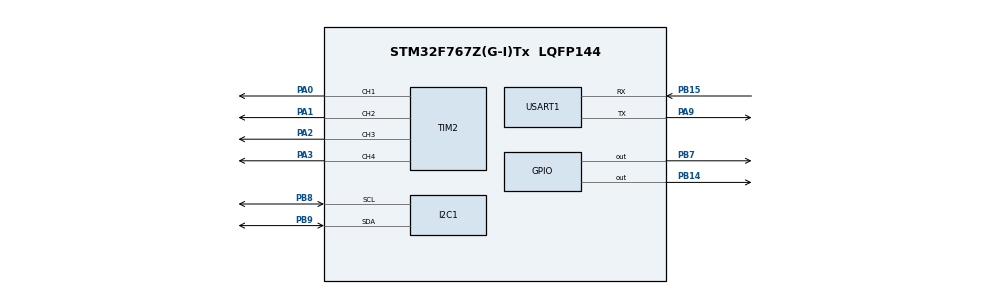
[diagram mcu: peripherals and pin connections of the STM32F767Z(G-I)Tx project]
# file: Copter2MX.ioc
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FATFS._USE_BUFF_WO_ALIGNMENT=2
FATFS._USE_ERASE=0
FREERTOS.INCLUDE_vTaskDelayUntil=1
FREERTOS.Tasks01=defaultTask,0,128,StartDefaultTask,Default,NULL,Dynamic,NULL,NULL;IMUTask,0,1024,ReadIMU,As external,NULL,Dynamic,NULL,NULL;DebugTask,-3,1024,WriteDebug,As external,NULL,Dynamic,NULL,NULL;PWMTask,0,1024,SetPWMOutput,As external,NULL,Dynamic,NULL,NULL;controllerTask,3,1024,StartController,As external,NULL,Dynamic,NULL,NULL
FREERTOS.configTOTAL_HEAP_SIZE=131072
FREERTOS.configUSE_ALTERNATIVE_API=0
I2C1.OwnAddress2Masks=I2C_OA2_NOMASK
Mcu.Family=STM32F7
Mcu.Name=STM32F767Z(G-I)Tx
Mcu.Package=LQFP144
NVIC.PriorityGroup=NVIC_PRIORITYGROUP_4
NVIC.USART1_IRQn=true\:5\:0\:false\:false\:true\:true
PA0/WKUP.Signal=S_TIM2_CH1_ETR
PA1.Signal=S_TIM2_CH2
PA2.Signal=S_TIM2_CH3
PA3.Signal=S_TIM2_CH4
PA9.Mode=Asynchronous
PA9.Signal=USART1_TX
PB14.Signal=GPIO_Output
PB15.Mode=Asynchronous
PB15.Signal=USART1_RX
PB7.Signal=GPIO_Output
PB8.Mode=I2C
PB8.Signal=I2C1_SCL
PB9.Mode=I2C
PB9.Signal=I2C1_SDA
ProjectManager.HeapSize=0x200
ProjectManager.StackSize=0x400
ProjectManager.TargetToolchain=SW4STM32
RCC.CECEnable=false
RCC.ClockTypeHCLK=RCC_CLOCKTYPE_HCLK
RCC.ClockTypePCLK1=RCC_CLOCKTYPE_PCLK1
RCC.ClockTypePCLK2=RCC_CLOCKTYPE_PCLK2
RCC.ClockTypeSysClk=RCC_CLOCKTYPE_SYSCLK
RCC.EnableHSE=false
RCC.EnableHSERTCDevisor=false
RCC.EnableLSE=false
RCC.EnableLSERTC=false
RCC.EnbaleCSS=false
RCC.ExtClockEnable=false
RCC.HSEState=RCC_HSE_OFF
RCC.HSE_VALUE=25000000
RCC.HSIState=RCC_HSI_ON
RCC.HSI_VALUE=16000000
RCC.I2C1Enable=true
RCC.I2C2Enable=false
RCC.I2C3Enable=false
RCC.I2C4Enable=false
RCC.I2SEnable=false
RCC.LCDEnable=false
RCC.LPTIM1Enable=false
RCC.LSE_VALUE=32768
RCC.LSIState=RCC_LSI_OFF
RCC.MCO1OutPutEnable=false
RCC.MCO2I2SEnable=false
RCC.MCO2OutPutEnable=false
RCC.OscillatorTypeHSI=RCC_OSCILLATORTYPE_HSI
RCC.PLLState=RCC_PLL_OFF
RCC.RCC_PERIPHCLK_I2C1Var=RCC_PERIPHCLK_I2C1
RCC.RCC_PERIPHCLK_USART1Var=RCC_PERIPHCLK_USART1
RCC.RTCEnable=false
RCC.SAI1Enable=false
RCC.SAI2Enable=false
RCC.SDMMC1Enable=false
RCC.SPDIFEnable=false
RCC.UART4Enable=false
RCC.UART5Enable=false
RCC.UART7Enable=false
RCC.UART8Enable=false
RCC.USART1Enable=true
RCC.USART2Enable=false
RCC.USART3Enable=false
RCC.USART6Enable=false
RCC.USBEnable=false
RCC.USBFreq_Value=96000000
RCC.VCOOutputFreq_Value=192000000
SH.S_TIM2_CH1_ETR.0=TIM2_CH1,PWM Generation1 CH1
SH.S_TIM2_CH2.0=TIM2_CH2,PWM Generation2 CH2
SH.S_TIM2_CH3.0=TIM2_CH3,PWM Generation3 CH3
SH.S_TIM2_CH4.0=TIM2_CH4,PWM Generation4 CH4
TIM2.Channel-PWM\ Generation1\ CH1=TIM_CHANNEL_1
TIM2.Channel-PWM\ Generation2\ CH2=TIM_CHANNEL_2
TIM2.Channel-PWM\ Generation3\ CH3=TIM_CHANNEL_3
TIM2.Channel-PWM\ Generation4\ CH4=TIM_CHANNEL_4
TIM2.ClearInputState=ENABLE
USART1.HwFlowCtl-Asynchronous=UART_HWCONTROL_NONE
USART1.VirtualMode-Asynchronous=VM_ASYNC
USART1.WordLength=WORDLENGTH_8B
VP_FATFS_VS_Generic.Mode=User_defined
VP_FREERTOS_VS_ENABLE.Mode=Enabled
board=Copter2MX

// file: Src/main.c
/**
  ******************************************************************************
  * File Name          : main.c
  * Description        : Main program body
  ******************************************************************************
  *
  * Copyright (c) 2017 STMicroelectronics International N.V.
  * All rights reserved.
  *
  * Redistribution and use in source and binary forms, with or without
  * modification, are permitted, provided that the following conditions are met:
  *
  * 1. Redistribution of source code must retain the above copyright notice,
  *    this list of conditions and the following disclaimer.
  * 2. Redistributions in binary form must reproduce the above copyright notice,
  *    this list of conditions and the following disclaimer in the documentation
  *    and/or other materials provided with the distribution.
  * 3. Neither the name of STMicroelectronics nor the names of other
  *    contributors to this software may be used to endorse or promote products
  *    derived from this software without specific written permission.
  * 4. This software, including modifications and/or derivative works of this
  *    software, must execute solely and exclusively on microcontroller or
  *    microprocessor devices manufactured by or for STMicroelectronics.
  * 5. Redistribution and use of this software other than as permitted under
  *    this license is void and will automatically terminate your rights under
  *    this license.
  *
  * THIS SOFTWARE IS PROVIDED BY STMICROELECTRONICS AND CONTRIBUTORS "AS IS"
  * AND ANY EXPRESS, IMPLIED OR STATUTORY WARRANTIES, INCLUDING, BUT NOT
  * LIMITED TO, THE IMPLIED WARRANTIES OF MERCHANTABILITY, FITNESS FOR A
  * PARTICULAR PURPOSE AND NON-INFRINGEMENT OF THIRD PARTY INTELLECTUAL PROPERTY
  * RIGHTS ARE DISCLAIMED TO THE FULLEST EXTENT PERMITTED BY LAW. IN NO EVENT
  * SHALL STMICROELECTRONICS OR CONTRIBUTORS BE LIABLE FOR ANY DIRECT, INDIRECT,
  * INCIDENTAL, SPECIAL, EXEMPLARY, OR CONSEQUENTIAL DAMAGES (INCLUDING, BUT NOT
  * LIMITED TO, PROCUREMENT OF SUBSTITUTE GOODS OR SERVICES; LOSS OF USE, DATA,
  * OR PROFITS; OR BUSINESS INTERRUPTION) HOWEVER CAUSED AND ON ANY THEORY OF
  * LIABILITY, WHETHER IN CONTRACT, STRICT LIABILITY, OR TORT (INCLUDING
  * NEGLIGENCE OR OTHERWISE) ARISING IN ANY WAY OUT OF THE USE OF THIS SOFTWARE,
  * EVEN IF ADVISED OF THE POSSIBILITY OF SUCH DAMAGE.
  *
  ******************************************************************************
  */
#include "main.h"
#include "stm32f7xx_hal.h"
#include "cmsis_os.h"
#include "fatfs.h"

/* USER CODE BEGIN Includes */
#include "DebugTask.h"
#include "sharedResources.h"

/* USER CODE END Includes */

I2C_HandleTypeDef hi2c1;

TIM_HandleTypeDef htim2;

UART_HandleTypeDef huart1;

osThreadId defaultTaskHandle;
osThreadId IMUTaskHandle;
osThreadId DebugTaskHandle;
osThreadId PWMTaskHandle;
osThreadId controllerTaskHandle;

/* USER CODE BEGIN PV */
/* Private variables ---------------------------------------------------------*/

/* USER CODE END PV */

void SystemClock_Config(void);
void Error_Handler(void);
static void MX_GPIO_Init(void);
static void MX_I2C1_Init(void);
static void MX_USART1_UART_Init(void);
static void MX_TIM2_Init(void);
void StartDefaultTask(void const * argument);
extern void ReadIMU(void const * argument);
extern void WriteDebug(void const * argument);
extern void SetPWMOutput(void const * argument);
extern void StartController(void const * argument);

void HAL_TIM_MspPostInit(TIM_HandleTypeDef *htim);

/* USER CODE BEGIN PFP */
/* Private function prototypes -----------------------------------------------*/

/* USER CODE END PFP */

int main(void)
{

  /* MCU Configuration----------------------------------------------------------*/

  /* Reset of all peripherals, Initializes the Flash interface and the Systick. */
  HAL_Init();

  /* Configure the system clock */
  SystemClock_Config();

  /* Initialize all configured peripherals */
  MX_GPIO_Init();
  MX_I2C1_Init();
  MX_USART1_UART_Init();
  MX_TIM2_Init();

  /* USER CODE BEGIN 2 */
  setDebugUartHandler(&huart1);
  initializeResources();
  /* USER CODE END 2 */

  /* Create the thread(s) */
  /* definition and creation of defaultTask */
  osThreadDef(defaultTask, StartDefaultTask, osPriorityNormal, 0, 128);
  defaultTaskHandle = osThreadCreate(osThread(defaultTask), NULL);

  /* definition and creation of IMUTask */
  osThreadDef(IMUTask, ReadIMU, osPriorityNormal, 0, 1024);
  IMUTaskHandle = osThreadCreate(osThread(IMUTask), NULL);

  /* definition and creation of DebugTask */
  osThreadDef(DebugTask, WriteDebug, osPriorityIdle, 0, 1024);
  DebugTaskHandle = osThreadCreate(osThread(DebugTask), NULL);

  /* definition and creation of PWMTask */
  osThreadDef(PWMTask, SetPWMOutput, osPriorityNormal, 0, 1024);
  PWMTaskHandle = osThreadCreate(osThread(PWMTask), NULL);

  /* definition and creation of controllerTask */
  osThreadDef(controllerTask, StartController, osPriorityRealtime, 0, 1024);
  controllerTaskHandle = osThreadCreate(osThread(controllerTask), NULL);

  /* Start scheduler */
  osKernelStart();

  /* We should never get here as control is now taken by the scheduler */

  /* Infinite loop */
  while (1)
  {

  }

}

/** System Clock Configuration
*/
void SystemClock_Config(void)
{

  RCC_OscInitTypeDef RCC_OscInitStruct;
  RCC_ClkInitTypeDef RCC_ClkInitStruct;
  RCC_PeriphCLKInitTypeDef PeriphClkInitStruct;

    /**Configure the main internal regulator output voltage
    */
  __HAL_RCC_PWR_CLK_ENABLE();

  __HAL_PWR_VOLTAGESCALING_CONFIG(PWR_REGULATOR_VOLTAGE_SCALE3);

    /**Initializes the CPU, AHB and APB busses clocks
    */
  RCC_OscInitStruct.OscillatorType = RCC_OSCILLATORTYPE_HSI;
  RCC_OscInitStruct.HSIState = RCC_HSI_ON;
  RCC_OscInitStruct.HSICalibrationValue = 16;
  RCC_OscInitStruct.PLL.PLLState = RCC_PLL_NONE;
  if (HAL_RCC_OscConfig(&RCC_OscInitStruct) != HAL_OK)
  {
    Error_Handler();
  }

    /**Initializes the CPU, AHB and APB busses clocks
    */
  RCC_ClkInitStruct.ClockType = RCC_CLOCKTYPE_HCLK|RCC_CLOCKTYPE_SYSCLK
                              |RCC_CLOCKTYPE_PCLK1|RCC_CLOCKTYPE_PCLK2;
  RCC_ClkInitStruct.SYSCLKSource = RCC_SYSCLKSOURCE_HSI;
  RCC_ClkInitStruct.AHBCLKDivider = RCC_SYSCLK_DIV1;
  RCC_ClkInitStruct.APB1CLKDivider = RCC_HCLK_DIV1;
  RCC_ClkInitStruct.APB2CLKDivider = RCC_HCLK_DIV1;

  if (HAL_RCC_ClockConfig(&RCC_ClkInitStruct, FLASH_LATENCY_0) != HAL_OK)
  {
    Error_Handler();
  }

  PeriphClkInitStruct.PeriphClockSelection = RCC_PERIPHCLK_USART1|RCC_PERIPHCLK_I2C1;
  PeriphClkInitStruct.Usart1ClockSelection = RCC_USART1CLKSOURCE_PCLK2;
  PeriphClkInitStruct.I2c1ClockSelection = RCC_I2C1CLKSOURCE_PCLK1;
  if (HAL_RCCEx_PeriphCLKConfig(&PeriphClkInitStruct) != HAL_OK)
  {
    Error_Handler();
  }

    /**Configure the Systick interrupt time
    */
  HAL_SYSTICK_Config(HAL_RCC_GetHCLKFreq()/1000);

    /**Configure the Systick
    */
  HAL_SYSTICK_CLKSourceConfig(SYSTICK_CLKSOURCE_HCLK);

  /* SysTick_IRQn interrupt configuration */
  HAL_NVIC_SetPriority(SysTick_IRQn, 15, 0);
}

/* I2C1 init function */
static void MX_I2C1_Init(void)
{

  hi2c1.Instance = I2C1;
  hi2c1.Init.Timing = 0x00303D5B;
  hi2c1.Init.OwnAddress1 = 0;
  hi2c1.Init.AddressingMode = I2C_ADDRESSINGMODE_7BIT;
  hi2c1.Init.DualAddressMode = I2C_DUALADDRESS_DISABLE;
  hi2c1.Init.OwnAddress2 = 0;
  hi2c1.Init.OwnAddress2Masks = I2C_OA2_NOMASK;
  hi2c1.Init.GeneralCallMode = I2C_GENERALCALL_DISABLE;
  hi2c1.Init.NoStretchMode = I2C_NOSTRETCH_DISABLE;
  if (HAL_I2C_Init(&hi2c1) != HAL_OK)
  {
    Error_Handler();
  }

    /**Configure Analogue filter
    */
  if (HAL_I2CEx_ConfigAnalogFilter(&hi2c1, I2C_ANALOGFILTER_ENABLE) != HAL_OK)
  {
    Error_Handler();
  }

    /**Configure Digital filter
    */
  if (HAL_I2CEx_ConfigDigitalFilter(&hi2c1, 0) != HAL_OK)
  {
    Error_Handler();
  }

}

/* TIM2 init function */
static void MX_TIM2_Init(void)
{

  TIM_MasterConfigTypeDef sMasterConfig;
  TIM_OC_InitTypeDef sConfigOC;

  htim2.Instance = TIM2;
  htim2.Init.Prescaler = 0;
  htim2.Init.CounterMode = TIM_COUNTERMODE_UP;
  htim2.Init.Period = 0;
  htim2.Init.ClockDivision = TIM_CLOCKDIVISION_DIV1;
  htim2.Init.AutoReloadPreload = TIM_AUTORELOAD_PRELOAD_DISABLE;
  if (HAL_TIM_PWM_Init(&htim2) != HAL_OK)
  {
    Error_Handler();
  }

  sMasterConfig.MasterOutputTrigger = TIM_TRGO_RESET;
  sMasterConfig.MasterSlaveMode = TIM_MASTERSLAVEMODE_DISABLE;
  if (HAL_TIMEx_MasterConfigSynchronization(&htim2, &sMasterConfig) != HAL_OK)
  {
    Error_Handler();
  }

  sConfigOC.OCMode = TIM_OCMODE_PWM1;
  sConfigOC.Pulse = 0;
  sConfigOC.OCPolarity = TIM_OCPOLARITY_HIGH;
  sConfigOC.OCFastMode = TIM_OCFAST_DISABLE;
  if (HAL_TIM_PWM_ConfigChannel(&htim2, &sConfigOC, TIM_CHANNEL_1) != HAL_OK)
  {
    Error_Handler();
  }

  if (HAL_TIM_PWM_ConfigChannel(&htim2, &sConfigOC, TIM_CHANNEL_2) != HAL_OK)
  {
    Error_Handler();
  }

  if (HAL_TIM_PWM_ConfigChannel(&htim2, &sConfigOC, TIM_CHANNEL_3) != HAL_OK)
  {
    Error_Handler();
  }

  if (HAL_TIM_PWM_ConfigChannel(&htim2, &sConfigOC, TIM_CHANNEL_4) != HAL_OK)
  {
    Error_Handler();
  }

  HAL_TIM_MspPostInit(&htim2);

}

/* USART1 init function */
static void MX_USART1_UART_Init(void)
{

  huart1.Instance = USART1;
  huart1.Init.BaudRate = 115200;
  huart1.Init.WordLength = UART_WORDLENGTH_8B;
  huart1.Init.StopBits = UART_STOPBITS_1;
  huart1.Init.Parity = UART_PARITY_NONE;
  huart1.Init.Mode = UART_MODE_TX_RX;
  huart1.Init.HwFlowCtl = UART_HWCONTROL_NONE;
  huart1.Init.OverSampling = UART_OVERSAMPLING_16;
  huart1.Init.OneBitSampling = UART_ONE_BIT_SAMPLE_DISABLE;
  huart1.AdvancedInit.AdvFeatureInit = UART_ADVFEATURE_NO_INIT;
  if (HAL_UART_Init(&huart1) != HAL_OK)
  {
    Error_Handler();
  }

}

/** Configure pins as
        * Analog
        * Input
        * Output
        * EVENT_OUT
        * EXTI
*/
static void MX_GPIO_Init(void)
{

  GPIO_InitTypeDef GPIO_InitStruct;

  /* GPIO Ports Clock Enable */
  __HAL_RCC_GPIOA_CLK_ENABLE();
  __HAL_RCC_GPIOB_CLK_ENABLE();

  /*Configure GPIO pin Output Level */
  HAL_GPIO_WritePin(GPIOB, GPIO_PIN_14|GPIO_PIN_7, GPIO_PIN_RESET);

  /*Configure GPIO pins : PB14 PB7 */
  GPIO_InitStruct.Pin = GPIO_PIN_14|GPIO_PIN_7;
  GPIO_InitStruct.Mode = GPIO_MODE_OUTPUT_PP;
  GPIO_InitStruct.Pull = GPIO_NOPULL;
  GPIO_InitStruct.Speed = GPIO_SPEED_FREQ_LOW;
  HAL_GPIO_Init(GPIOB, &GPIO_InitStruct);

}

/* StartDefaultTask function */
void StartDefaultTask(void const * argument)
{
  /* init code for FATFS */
  MX_FATFS_Init();

  for(;;)
  {
    osDelay(1);
  }
}

void Error_Handler(void)
{
  while(1)
  {
  }
}

/************************ (C) COPYRIGHT STMicroelectronics *****END OF FILE****/
